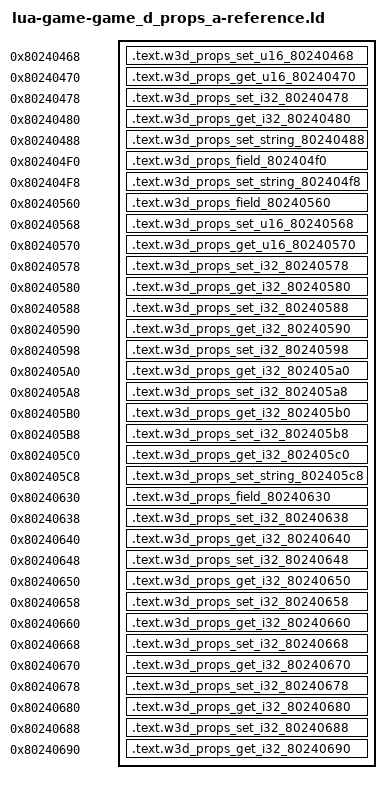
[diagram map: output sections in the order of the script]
/* Generated reference-only placements. All bodies are source-built. */
OUTPUT_FORMAT("elf32-powerpc")
OUTPUT_ARCH(powerpc)
ENTRY(w3d_props_set_u16_80240468)
_SDA_BASE_ = 0x804b2540;
_SDA2_BASE_ = 0x804c2540;
w3d_string_release_header = 0x8020bb2c;
SECTIONS {
  .text.w3d_props_set_u16_80240468 0x80240468 : { *(.text.w3d_props_set_u16_80240468) }
  .text.w3d_props_get_u16_80240470 0x80240470 : { *(.text.w3d_props_get_u16_80240470) }
  .text.w3d_props_set_i32_80240478 0x80240478 : { *(.text.w3d_props_set_i32_80240478) }
  .text.w3d_props_get_i32_80240480 0x80240480 : { *(.text.w3d_props_get_i32_80240480) }
  .text.w3d_props_set_string_80240488 0x80240488 : { *(.text.w3d_props_set_string_80240488) }
  .text.w3d_props_field_802404f0 0x802404f0 : { *(.text.w3d_props_field_802404f0) }
  .text.w3d_props_set_string_802404f8 0x802404f8 : { *(.text.w3d_props_set_string_802404f8) }
  .text.w3d_props_field_80240560 0x80240560 : { *(.text.w3d_props_field_80240560) }
  .text.w3d_props_set_u16_80240568 0x80240568 : { *(.text.w3d_props_set_u16_80240568) }
  .text.w3d_props_get_u16_80240570 0x80240570 : { *(.text.w3d_props_get_u16_80240570) }
  .text.w3d_props_set_i32_80240578 0x80240578 : { *(.text.w3d_props_set_i32_80240578) }
  .text.w3d_props_get_i32_80240580 0x80240580 : { *(.text.w3d_props_get_i32_80240580) }
  .text.w3d_props_set_i32_80240588 0x80240588 : { *(.text.w3d_props_set_i32_80240588) }
  .text.w3d_props_get_i32_80240590 0x80240590 : { *(.text.w3d_props_get_i32_80240590) }
  .text.w3d_props_set_i32_80240598 0x80240598 : { *(.text.w3d_props_set_i32_80240598) }
  .text.w3d_props_get_i32_802405a0 0x802405a0 : { *(.text.w3d_props_get_i32_802405a0) }
  .text.w3d_props_set_i32_802405a8 0x802405a8 : { *(.text.w3d_props_set_i32_802405a8) }
  .text.w3d_props_get_i32_802405b0 0x802405b0 : { *(.text.w3d_props_get_i32_802405b0) }
  .text.w3d_props_set_i32_802405b8 0x802405b8 : { *(.text.w3d_props_set_i32_802405b8) }
  .text.w3d_props_get_i32_802405c0 0x802405c0 : { *(.text.w3d_props_get_i32_802405c0) }
  .text.w3d_props_set_string_802405c8 0x802405c8 : { *(.text.w3d_props_set_string_802405c8) }
  .text.w3d_props_field_80240630 0x80240630 : { *(.text.w3d_props_field_80240630) }
  .text.w3d_props_set_i32_80240638 0x80240638 : { *(.text.w3d_props_set_i32_80240638) }
  .text.w3d_props_get_i32_80240640 0x80240640 : { *(.text.w3d_props_get_i32_80240640) }
  .text.w3d_props_set_i32_80240648 0x80240648 : { *(.text.w3d_props_set_i32_80240648) }
  .text.w3d_props_get_i32_80240650 0x80240650 : { *(.text.w3d_props_get_i32_80240650) }
  .text.w3d_props_set_i32_80240658 0x80240658 : { *(.text.w3d_props_set_i32_80240658) }
  .text.w3d_props_get_i32_80240660 0x80240660 : { *(.text.w3d_props_get_i32_80240660) }
  .text.w3d_props_set_i32_80240668 0x80240668 : { *(.text.w3d_props_set_i32_80240668) }
  .text.w3d_props_get_i32_80240670 0x80240670 : { *(.text.w3d_props_get_i32_80240670) }
  .text.w3d_props_set_i32_80240678 0x80240678 : { *(.text.w3d_props_set_i32_80240678) }
  .text.w3d_props_get_i32_80240680 0x80240680 : { *(.text.w3d_props_get_i32_80240680) }
  .text.w3d_props_set_i32_80240688 0x80240688 : { *(.text.w3d_props_set_i32_80240688) }
  .text.w3d_props_get_i32_80240690 0x80240690 : { *(.text.w3d_props_get_i32_80240690) }
  /DISCARD/ : { *(.text*) *(.rodata*) *(.data*) *(.bss*) *(.sdata*) *(.sbss*) *(.comment) }
}
